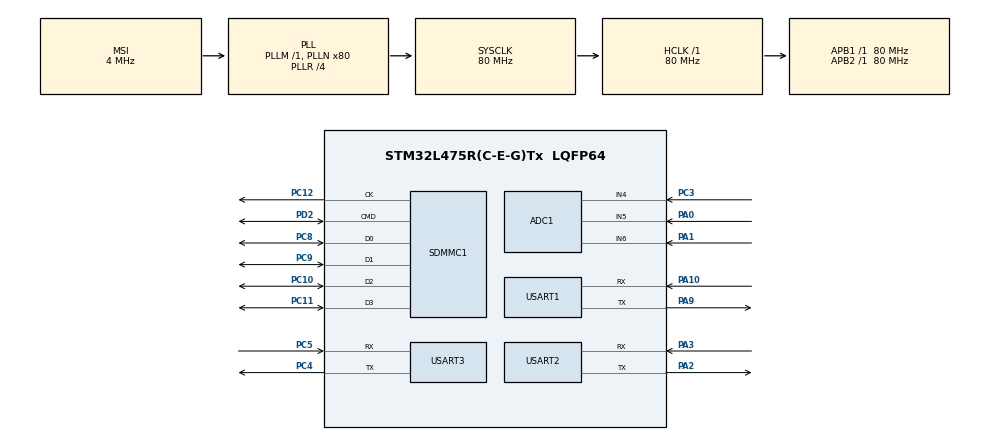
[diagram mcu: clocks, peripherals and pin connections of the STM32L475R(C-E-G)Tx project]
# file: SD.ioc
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ADC1.Channel-0\#ChannelRegularConversion=ADC_CHANNEL_4
ADC1.Channel-1\#ChannelRegularConversion=ADC_CHANNEL_5
ADC1.Channel-2\#ChannelRegularConversion=ADC_CHANNEL_6
ADC1.NbrOfConversion=3
ADC1.NbrOfConversionFlag=1
ADC1.OffsetNumber-0\#ChannelRegularConversion=ADC_OFFSET_NONE
ADC1.OffsetNumber-1\#ChannelRegularConversion=ADC_OFFSET_NONE
ADC1.OffsetNumber-2\#ChannelRegularConversion=ADC_OFFSET_NONE
ADC1.Rank-0\#ChannelRegularConversion=1
ADC1.Rank-1\#ChannelRegularConversion=2
ADC1.Rank-2\#ChannelRegularConversion=3
ADC1.SamplingTime-0\#ChannelRegularConversion=ADC_SAMPLETIME_2CYCLES_5
ADC1.SamplingTime-1\#ChannelRegularConversion=ADC_SAMPLETIME_2CYCLES_5
ADC1.SamplingTime-2\#ChannelRegularConversion=ADC_SAMPLETIME_2CYCLES_5
ADC1.master=1
FATFS.USE_DMA_CODE_SD=0
FATFS._MAX_SS=4096
Mcu.Family=STM32L4
Mcu.Name=STM32L475R(C-E-G)Tx
Mcu.Package=LQFP64
NVIC.ADC1_2_IRQn=true\:0\:0\:false\:false\:true\:true\:true
NVIC.PriorityGroup=NVIC_PRIORITYGROUP_4
NVIC.SDMMC1_IRQn=true\:0\:0\:false\:false\:true\:true\:true
NVIC.TIM1_UP_TIM16_IRQn=true\:0\:0\:false\:false\:true\:true\:true
NVIC.TIM5_IRQn=true\:0\:0\:false\:false\:true\:true\:true
NVIC.TIM6_DAC_IRQn=true\:0\:0\:false\:false\:true\:true\:true
NVIC.USART1_IRQn=true\:0\:0\:false\:false\:true\:true\:true
NVIC.USART2_IRQn=true\:0\:0\:false\:false\:true\:true\:true
NVIC.USART3_IRQn=true\:0\:0\:false\:false\:true\:true\:true
PA0.Signal=ADCx_IN5
PA1.Signal=ADCx_IN6
PA10.Mode=Asynchronous
PA10.Signal=USART1_RX
PA2.Mode=Asynchronous
PA2.Signal=USART2_TX
PA3.Mode=Asynchronous
PA3.Signal=USART2_RX
PA9.Mode=Asynchronous
PA9.Signal=USART1_TX
PC10.GPIO_PuPd=GPIO_PULLUP
PC10.Mode=SD_4_bits_Wide_bus
PC10.Signal=SDMMC1_D2
PC11.GPIO_PuPd=GPIO_PULLUP
PC11.Mode=SD_4_bits_Wide_bus
PC11.Signal=SDMMC1_D3
PC12.Mode=SD_4_bits_Wide_bus
PC12.Signal=SDMMC1_CK
PC3.Signal=ADCx_IN4
PC4.Mode=Asynchronous
PC4.Signal=USART3_TX
PC5.Mode=Asynchronous
PC5.Signal=USART3_RX
PC8.GPIO_PuPd=GPIO_PULLUP
PC8.Mode=SD_4_bits_Wide_bus
PC8.Signal=SDMMC1_D0
PC9.GPIO_PuPd=GPIO_PULLUP
PC9.Mode=SD_4_bits_Wide_bus
PC9.Signal=SDMMC1_D1
PD2.GPIO_PuPd=GPIO_PULLUP
PD2.Mode=SD_4_bits_Wide_bus
PD2.Signal=SDMMC1_CMD
ProjectManager.HeapSize=0x200
ProjectManager.StackSize=0x400
ProjectManager.TargetToolchain=TrueSTUDIO
RCC.ADCFreq_Value=40000000
RCC.AHBFreq_Value=80000000
RCC.APB1Freq_Value=80000000
RCC.APB1TimFreq_Value=80000000
RCC.APB2Freq_Value=80000000
RCC.APB2TimFreq_Value=80000000
RCC.CortexFreq_Value=80000000
RCC.HCLKFreq_Value=80000000
RCC.HSE_VALUE=8000000
RCC.HSI_VALUE=16000000
RCC.LSE_VALUE=32768
RCC.MSI_VALUE=4000000
RCC.PLLN=80
RCC.PLLR=RCC_PLLR_DIV4
RCC.PLLSAI1N=20
RCC.SYSCLKFreq_VALUE=80000000
RCC.SYSCLKSource=RCC_SYSCLKSOURCE_PLLCLK
RCC.USBFreq_Value=40000000
RCC.VCOOutputFreq_Value=320000000
SH.ADCx_IN4.0=ADC1_IN4,IN4-Single-Ended
SH.ADCx_IN5.0=ADC1_IN5,IN5-Single-Ended
SH.ADCx_IN6.0=ADC1_IN6,IN6-Single-Ended
TIM16.Period=1000
TIM5.Period=1000
TIM6.Period=1000
USART1.VirtualMode-Asynchronous=VM_ASYNC
USART2.VirtualMode-Asynchronous=VM_ASYNC
USART3.VirtualMode-Asynchronous=VM_ASYNC
VP_FATFS_VS_SDIO.Mode=SDIO
VP_RTC_VS_RTC_Activate.Mode=RTC_Enabled
VP_TIM16_VS_ClockSourceINT.Mode=Enable_Timer
VP_TIM5_VS_ClockSourceINT.Mode=Internal
VP_TIM6_VS_ClockSourceINT.Mode=Enable_Timer
board=SD

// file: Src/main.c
/* USER CODE BEGIN Header */
/**
  ******************************************************************************
  * @file           : main.c
  * @brief          : Main program body
  ******************************************************************************
  * @attention
  *
  * <h2><center>&copy; Copyright (c) 2019 STMicroelectronics.
  * All rights reserved.</center></h2>
  *
  * This software component is licensed by ST under Ultimate Liberty license
  * SLA0044, the "License"; You may not use this file except in compliance with
  * the License. You may obtain a copy of the License at:
  *                             www.st.com/SLA0044
  *
  ******************************************************************************
  */
/* USER CODE END Header */

#include "main.h"
#include "fatfs.h"

ADC_HandleTypeDef hadc1;

RTC_HandleTypeDef hrtc;

SD_HandleTypeDef hsd1;

TIM_HandleTypeDef htim5;
TIM_HandleTypeDef htim6;
TIM_HandleTypeDef htim16;

UART_HandleTypeDef huart1;
UART_HandleTypeDef huart2;
UART_HandleTypeDef huart3;

/* USER CODE BEGIN PV */
/* Private variables ---------------------------------------------------------*/

/* USER CODE END PV */

void SystemClock_Config(void);
static void MX_GPIO_Init(void);
static void MX_SDMMC1_SD_Init(void);
static void MX_USART1_UART_Init(void);
static void MX_USART2_UART_Init(void);
static void MX_TIM5_Init(void);
static void MX_TIM6_Init(void);
static void MX_TIM16_Init(void);
static void MX_USART3_UART_Init(void);
static void MX_ADC1_Init(void);
static void MX_RTC_Init(void);
/* USER CODE BEGIN PFP */
/* Private function prototypes -----------------------------------------------*/

/* USER CODE END PFP */

/* USER CODE BEGIN 0 */
FATFS SDFatFs;  /* File system object for SD card logical drive */

FIL MyFile;     /* File object */

char SD_Path[4];  /* SD logical drive path */
/* USER CODE END 0 */

int main(void)
{

  /* MCU Configuration--------------------------------------------------------*/

  /* Reset of all peripherals, Initializes the Flash interface and the Systick. */
  HAL_Init();

  /* Configure the system clock */
  SystemClock_Config();

  /* Initialize all configured peripherals */
  MX_GPIO_Init();
  MX_SDMMC1_SD_Init();
  MX_FATFS_Init();
  MX_USART1_UART_Init();
  MX_USART2_UART_Init();
  MX_TIM5_Init();
  MX_TIM6_Init();
  MX_TIM16_Init();
  MX_USART3_UART_Init();
  MX_ADC1_Init();
  MX_RTC_Init();
  /* USER CODE BEGIN 2 */
//  BSP_SD_Init();
//  HAL_Delay(200);
//  MX_FATFS_Init();

  /* USER CODE END 2 */

  /* Infinite loop */
  /* USER CODE BEGIN WHILE */
  FRESULT res = f_mount(&SDFatFs, (TCHAR const*)SD_Path, 1);
	 if(res != FR_OK)
	    Error_Handler();
	  else
	  {
		  uint8_t arr[] = {0, 1, 2};
		  uint8_t arrrd[20];
		  uint8_t* bw;
		  res = f_open(&MyFile, "adr.txt", FA_READ|FA_WRITE);
		  res = f_read(&MyFile, arrrd, 10, bw);
		  res = f_write(&MyFile, arr, 3, bw);
//          if(f_open(&MyFile, ".\adr.txt", FA_READ) != FR_OK)
//                    Error_Handler();
//            else
//            {
//                          f_close(&MyFile);
//            }
	  }
  while (1)
  {

    /* USER CODE END WHILE */

  }
}

void SystemClock_Config(void)
{
  RCC_OscInitTypeDef RCC_OscInitStruct = {0};
  RCC_ClkInitTypeDef RCC_ClkInitStruct = {0};
  RCC_PeriphCLKInitTypeDef PeriphClkInit = {0};

  /** Initializes the CPU, AHB and APB busses clocks
  */
  RCC_OscInitStruct.OscillatorType = RCC_OSCILLATORTYPE_LSI|RCC_OSCILLATORTYPE_MSI;
  RCC_OscInitStruct.LSIState = RCC_LSI_ON;
  RCC_OscInitStruct.MSIState = RCC_MSI_ON;
  RCC_OscInitStruct.MSICalibrationValue = 0;
  RCC_OscInitStruct.MSIClockRange = RCC_MSIRANGE_6;
  RCC_OscInitStruct.PLL.PLLState = RCC_PLL_ON;
  RCC_OscInitStruct.PLL.PLLSource = RCC_PLLSOURCE_MSI;
  RCC_OscInitStruct.PLL.PLLM = 1;
  RCC_OscInitStruct.PLL.PLLN = 80;
  RCC_OscInitStruct.PLL.PLLP = RCC_PLLP_DIV7;
  RCC_OscInitStruct.PLL.PLLQ = RCC_PLLQ_DIV2;
  RCC_OscInitStruct.PLL.PLLR = RCC_PLLR_DIV4;
  if (HAL_RCC_OscConfig(&RCC_OscInitStruct) != HAL_OK)
  {
    Error_Handler();
  }
  /** Initializes the CPU, AHB and APB busses clocks
  */
  RCC_ClkInitStruct.ClockType = RCC_CLOCKTYPE_HCLK|RCC_CLOCKTYPE_SYSCLK
                              |RCC_CLOCKTYPE_PCLK1|RCC_CLOCKTYPE_PCLK2;
  RCC_ClkInitStruct.SYSCLKSource = RCC_SYSCLKSOURCE_PLLCLK;
  RCC_ClkInitStruct.AHBCLKDivider = RCC_SYSCLK_DIV1;
  RCC_ClkInitStruct.APB1CLKDivider = RCC_HCLK_DIV1;
  RCC_ClkInitStruct.APB2CLKDivider = RCC_HCLK_DIV1;

  if (HAL_RCC_ClockConfig(&RCC_ClkInitStruct, FLASH_LATENCY_4) != HAL_OK)
  {
    Error_Handler();
  }
  PeriphClkInit.PeriphClockSelection = RCC_PERIPHCLK_RTC|RCC_PERIPHCLK_USART1
                              |RCC_PERIPHCLK_USART2|RCC_PERIPHCLK_USART3
                              |RCC_PERIPHCLK_SDMMC1|RCC_PERIPHCLK_ADC;
  PeriphClkInit.Usart1ClockSelection = RCC_USART1CLKSOURCE_PCLK2;
  PeriphClkInit.Usart2ClockSelection = RCC_USART2CLKSOURCE_PCLK1;
  PeriphClkInit.Usart3ClockSelection = RCC_USART3CLKSOURCE_PCLK1;
  PeriphClkInit.AdcClockSelection = RCC_ADCCLKSOURCE_PLLSAI1;
  PeriphClkInit.RTCClockSelection = RCC_RTCCLKSOURCE_LSI;
  PeriphClkInit.Sdmmc1ClockSelection = RCC_SDMMC1CLKSOURCE_PLLSAI1;
  PeriphClkInit.PLLSAI1.PLLSAI1Source = RCC_PLLSOURCE_MSI;
  PeriphClkInit.PLLSAI1.PLLSAI1M = 1;
  PeriphClkInit.PLLSAI1.PLLSAI1N = 20;
  PeriphClkInit.PLLSAI1.PLLSAI1P = RCC_PLLP_DIV7;
  PeriphClkInit.PLLSAI1.PLLSAI1Q = RCC_PLLQ_DIV2;
  PeriphClkInit.PLLSAI1.PLLSAI1R = RCC_PLLR_DIV2;
  PeriphClkInit.PLLSAI1.PLLSAI1ClockOut = RCC_PLLSAI1_48M2CLK|RCC_PLLSAI1_ADC1CLK;
  if (HAL_RCCEx_PeriphCLKConfig(&PeriphClkInit) != HAL_OK)
  {
    Error_Handler();
  }
  /** Configure the main internal regulator output voltage
  */
  if (HAL_PWREx_ControlVoltageScaling(PWR_REGULATOR_VOLTAGE_SCALE1) != HAL_OK)
  {
    Error_Handler();
  }
}

static void MX_ADC1_Init(void)
{

  ADC_MultiModeTypeDef multimode = {0};
  ADC_ChannelConfTypeDef sConfig = {0};

  /** Common config
  */
  hadc1.Instance = ADC1;
  hadc1.Init.ClockPrescaler = ADC_CLOCK_ASYNC_DIV1;
  hadc1.Init.Resolution = ADC_RESOLUTION_12B;
  hadc1.Init.DataAlign = ADC_DATAALIGN_RIGHT;
  hadc1.Init.ScanConvMode = ADC_SCAN_ENABLE;
  hadc1.Init.EOCSelection = ADC_EOC_SINGLE_CONV;
  hadc1.Init.LowPowerAutoWait = DISABLE;
  hadc1.Init.ContinuousConvMode = DISABLE;
  hadc1.Init.NbrOfConversion = 3;
  hadc1.Init.DiscontinuousConvMode = DISABLE;
  hadc1.Init.ExternalTrigConv = ADC_SOFTWARE_START;
  hadc1.Init.ExternalTrigConvEdge = ADC_EXTERNALTRIGCONVEDGE_NONE;
  hadc1.Init.DMAContinuousRequests = DISABLE;
  hadc1.Init.Overrun = ADC_OVR_DATA_PRESERVED;
  hadc1.Init.OversamplingMode = DISABLE;
  if (HAL_ADC_Init(&hadc1) != HAL_OK)
  {
    Error_Handler();
  }
  /** Configure the ADC multi-mode
  */
  multimode.Mode = ADC_MODE_INDEPENDENT;
  if (HAL_ADCEx_MultiModeConfigChannel(&hadc1, &multimode) != HAL_OK)
  {
    Error_Handler();
  }
  /** Configure Regular Channel
  */
  sConfig.Channel = ADC_CHANNEL_4;
  sConfig.Rank = ADC_REGULAR_RANK_1;
  sConfig.SamplingTime = ADC_SAMPLETIME_2CYCLES_5;
  sConfig.SingleDiff = ADC_SINGLE_ENDED;
  sConfig.OffsetNumber = ADC_OFFSET_NONE;
  sConfig.Offset = 0;
  if (HAL_ADC_ConfigChannel(&hadc1, &sConfig) != HAL_OK)
  {
    Error_Handler();
  }
  /** Configure Regular Channel
  */
  sConfig.Channel = ADC_CHANNEL_5;
  sConfig.Rank = ADC_REGULAR_RANK_2;
  if (HAL_ADC_ConfigChannel(&hadc1, &sConfig) != HAL_OK)
  {
    Error_Handler();
  }
  /** Configure Regular Channel
  */
  sConfig.Channel = ADC_CHANNEL_6;
  sConfig.Rank = ADC_REGULAR_RANK_3;
  if (HAL_ADC_ConfigChannel(&hadc1, &sConfig) != HAL_OK)
  {
    Error_Handler();
  }

}

static void MX_RTC_Init(void)
{

  /** Initialize RTC Only
  */
  hrtc.Instance = RTC;
  hrtc.Init.HourFormat = RTC_HOURFORMAT_24;
  hrtc.Init.AsynchPrediv = 127;
  hrtc.Init.SynchPrediv = 255;
  hrtc.Init.OutPut = RTC_OUTPUT_DISABLE;
  hrtc.Init.OutPutRemap = RTC_OUTPUT_REMAP_NONE;
  hrtc.Init.OutPutPolarity = RTC_OUTPUT_POLARITY_HIGH;
  hrtc.Init.OutPutType = RTC_OUTPUT_TYPE_OPENDRAIN;
  if (HAL_RTC_Init(&hrtc) != HAL_OK)
  {
    Error_Handler();
  }

}

static void MX_SDMMC1_SD_Init(void)
{

  hsd1.Instance = SDMMC1;
  hsd1.Init.ClockEdge = SDMMC_CLOCK_EDGE_RISING;
  hsd1.Init.ClockBypass = SDMMC_CLOCK_BYPASS_DISABLE;
  hsd1.Init.ClockPowerSave = SDMMC_CLOCK_POWER_SAVE_DISABLE;
  hsd1.Init.BusWide = SDMMC_BUS_WIDE_1B;
  hsd1.Init.HardwareFlowControl = SDMMC_HARDWARE_FLOW_CONTROL_DISABLE;
  hsd1.Init.ClockDiv = 0;

}

static void MX_TIM5_Init(void)
{

  TIM_ClockConfigTypeDef sClockSourceConfig = {0};
  TIM_MasterConfigTypeDef sMasterConfig = {0};

  htim5.Instance = TIM5;
  htim5.Init.Prescaler = 0;
  htim5.Init.CounterMode = TIM_COUNTERMODE_UP;
  htim5.Init.Period = 1000;
  htim5.Init.ClockDivision = TIM_CLOCKDIVISION_DIV1;
  htim5.Init.AutoReloadPreload = TIM_AUTORELOAD_PRELOAD_DISABLE;
  if (HAL_TIM_Base_Init(&htim5) != HAL_OK)
  {
    Error_Handler();
  }
  sClockSourceConfig.ClockSource = TIM_CLOCKSOURCE_INTERNAL;
  if (HAL_TIM_ConfigClockSource(&htim5, &sClockSourceConfig) != HAL_OK)
  {
    Error_Handler();
  }
  sMasterConfig.MasterOutputTrigger = TIM_TRGO_RESET;
  sMasterConfig.MasterSlaveMode = TIM_MASTERSLAVEMODE_DISABLE;
  if (HAL_TIMEx_MasterConfigSynchronization(&htim5, &sMasterConfig) != HAL_OK)
  {
    Error_Handler();
  }

}

static void MX_TIM6_Init(void)
{

  TIM_MasterConfigTypeDef sMasterConfig = {0};

  htim6.Instance = TIM6;
  htim6.Init.Prescaler = 0;
  htim6.Init.CounterMode = TIM_COUNTERMODE_UP;
  htim6.Init.Period = 1000;
  htim6.Init.AutoReloadPreload = TIM_AUTORELOAD_PRELOAD_DISABLE;
  if (HAL_TIM_Base_Init(&htim6) != HAL_OK)
  {
    Error_Handler();
  }
  sMasterConfig.MasterOutputTrigger = TIM_TRGO_RESET;
  sMasterConfig.MasterSlaveMode = TIM_MASTERSLAVEMODE_DISABLE;
  if (HAL_TIMEx_MasterConfigSynchronization(&htim6, &sMasterConfig) != HAL_OK)
  {
    Error_Handler();
  }

}

static void MX_TIM16_Init(void)
{

  htim16.Instance = TIM16;
  htim16.Init.Prescaler = 0;
  htim16.Init.CounterMode = TIM_COUNTERMODE_UP;
  htim16.Init.Period = 1000;
  htim16.Init.ClockDivision = TIM_CLOCKDIVISION_DIV1;
  htim16.Init.RepetitionCounter = 0;
  htim16.Init.AutoReloadPreload = TIM_AUTORELOAD_PRELOAD_DISABLE;
  if (HAL_TIM_Base_Init(&htim16) != HAL_OK)
  {
    Error_Handler();
  }

}

static void MX_USART1_UART_Init(void)
{

  huart1.Instance = USART1;
  huart1.Init.BaudRate = 115200;
  huart1.Init.WordLength = UART_WORDLENGTH_8B;
  huart1.Init.StopBits = UART_STOPBITS_1;
  huart1.Init.Parity = UART_PARITY_NONE;
  huart1.Init.Mode = UART_MODE_TX_RX;
  huart1.Init.HwFlowCtl = UART_HWCONTROL_NONE;
  huart1.Init.OverSampling = UART_OVERSAMPLING_16;
  huart1.Init.OneBitSampling = UART_ONE_BIT_SAMPLE_DISABLE;
  huart1.AdvancedInit.AdvFeatureInit = UART_ADVFEATURE_NO_INIT;
  if (HAL_UART_Init(&huart1) != HAL_OK)
  {
    Error_Handler();
  }

}

static void MX_USART2_UART_Init(void)
{

  huart2.Instance = USART2;
  huart2.Init.BaudRate = 115200;
  huart2.Init.WordLength = UART_WORDLENGTH_8B;
  huart2.Init.StopBits = UART_STOPBITS_1;
  huart2.Init.Parity = UART_PARITY_NONE;
  huart2.Init.Mode = UART_MODE_TX_RX;
  huart2.Init.HwFlowCtl = UART_HWCONTROL_NONE;
  huart2.Init.OverSampling = UART_OVERSAMPLING_16;
  huart2.Init.OneBitSampling = UART_ONE_BIT_SAMPLE_DISABLE;
  huart2.AdvancedInit.AdvFeatureInit = UART_ADVFEATURE_NO_INIT;
  if (HAL_UART_Init(&huart2) != HAL_OK)
  {
    Error_Handler();
  }

}

static void MX_USART3_UART_Init(void)
{

  huart3.Instance = USART3;
  huart3.Init.BaudRate = 115200;
  huart3.Init.WordLength = UART_WORDLENGTH_8B;
  huart3.Init.StopBits = UART_STOPBITS_1;
  huart3.Init.Parity = UART_PARITY_NONE;
  huart3.Init.Mode = UART_MODE_TX_RX;
  huart3.Init.HwFlowCtl = UART_HWCONTROL_NONE;
  huart3.Init.OverSampling = UART_OVERSAMPLING_16;
  huart3.Init.OneBitSampling = UART_ONE_BIT_SAMPLE_DISABLE;
  huart3.AdvancedInit.AdvFeatureInit = UART_ADVFEATURE_NO_INIT;
  if (HAL_UART_Init(&huart3) != HAL_OK)
  {
    Error_Handler();
  }

}

static void MX_GPIO_Init(void)
{

  /* GPIO Ports Clock Enable */
  __HAL_RCC_GPIOC_CLK_ENABLE();
  __HAL_RCC_GPIOA_CLK_ENABLE();
  __HAL_RCC_GPIOD_CLK_ENABLE();

}

void Error_Handler(void)
{
  while(1)
  {
  }
}

/************************ (C) COPYRIGHT STMicroelectronics *****END OF FILE****/
